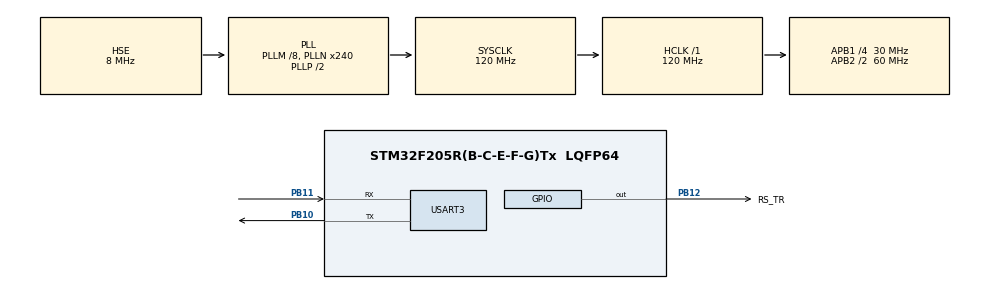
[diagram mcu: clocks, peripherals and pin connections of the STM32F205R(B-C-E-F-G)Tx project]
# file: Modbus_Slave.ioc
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Mcu.Family=STM32F2
Mcu.Name=STM32F205R(B-C-E-F-G)Tx
Mcu.Package=LQFP64
NVIC.PriorityGroup=NVIC_PRIORITYGROUP_4
NVIC.TIM5_IRQn=true\:0\:0\:false\:false\:true\:true\:true\:true
NVIC.USART3_IRQn=true\:0\:0\:false\:false\:true\:true\:true\:true
PA13.Mode=Serial_Wire
PA13.Signal=SYS_JTMS-SWDIO
PA14.Mode=Serial_Wire
PA14.Signal=SYS_JTCK-SWCLK
PB10.Mode=Asynchronous
PB10.Signal=USART3_TX
PB11.Mode=Asynchronous
PB11.Signal=USART3_RX
PB12.GPIO_Label=RS_TR
PB12.Signal=GPIO_Output
PH0-OSC_IN.Mode=HSE-External-Oscillator
PH0-OSC_IN.Signal=RCC_OSC_IN
PH1-OSC_OUT.Mode=HSE-External-Oscillator
PH1-OSC_OUT.Signal=RCC_OSC_OUT
ProjectManager.HeapSize=0x400
ProjectManager.StackSize=0x800
ProjectManager.TargetToolchain=MDK-ARM V5.32
RCC.48MHZClocksFreq_Value=60000000
RCC.AHBFreq_Value=120000000
RCC.APB1CLKDivider=RCC_HCLK_DIV4
RCC.APB1Freq_Value=30000000
RCC.APB1TimFreq_Value=60000000
RCC.APB2CLKDivider=RCC_HCLK_DIV2
RCC.APB2Freq_Value=60000000
RCC.APB2TimFreq_Value=120000000
RCC.CortexFreq_Value=120000000
RCC.HCLKFreq_Value=120000000
RCC.HSE_VALUE=8000000
RCC.HSI_VALUE=16000000
RCC.LSE_VALUE=32768
RCC.PLLM=8
RCC.PLLN=240
RCC.PLLSourceVirtual=RCC_PLLSOURCE_HSE
RCC.SYSCLKFreq_VALUE=120000000
RCC.SYSCLKSource=RCC_SYSCLKSOURCE_PLLCLK
RCC.VCOOutputFreq_Value=240000000
TIM5.Period=50
TIM5.Prescaler=60-1
USART3.VirtualMode=VM_ASYNC
VP_TIM5_VS_ClockSourceINT.Mode=Internal
board=custom

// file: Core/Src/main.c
/* USER CODE BEGIN Header */
/**
  ******************************************************************************
  * @file           : main.c
  * @brief          : Main program body
  ******************************************************************************
  * @attention
  *
  * Copyright (c) 2025 STMicroelectronics.
  * All rights reserved.
  *
  * This software is licensed under terms that can be found in the LICENSE file
  * in the root directory of this software component.
  * If no LICENSE file comes with this software, it is provided AS-IS.
  *
  ******************************************************************************
  */
/* USER CODE END Header */
#include "main.h"
#include "tim.h"
#include "usart.h"
#include "gpio.h"

/* USER CODE BEGIN Includes */
#include "modbus_slave.h"
/* USER CODE END Includes */

/* USER CODE BEGIN PV */
extern volatile USHORT usRegInputStart;
extern volatile USHORT usRegInputBuf[REG_INPUT_NREGS];
/* USER CODE END PV */

void SystemClock_Config(void);

int main(void)
{

  /* MCU Configuration--------------------------------------------------------*/

  /* Reset of all peripherals, Initializes the Flash interface and the Systick. */
  HAL_Init();

  /* Configure the system clock */
  SystemClock_Config();

  /* Initialize all configured peripherals */
  MX_GPIO_Init();
  MX_TIM5_Init();
  MX_USART3_UART_Init();
  /* USER CODE BEGIN 2 */
	modbusInit();
  /* USER CODE END 2 */

  /* Infinite loop */
  while (1)
  {

    /* USER CODE BEGIN 3 */
		eMBPoll();
    usRegInputBuf[REG_INPUT_NREGS - 2] =  HAL_GetTick() / 1000;
    usRegInputBuf[REG_INPUT_NREGS - 1] =  HAL_GetTick();
  }
  /* USER CODE END 3 */
}

void SystemClock_Config(void)
{
  RCC_OscInitTypeDef RCC_OscInitStruct = {0};
  RCC_ClkInitTypeDef RCC_ClkInitStruct = {0};

  /** Initializes the RCC Oscillators according to the specified parameters
  * in the RCC_OscInitTypeDef structure.
  */
  RCC_OscInitStruct.OscillatorType = RCC_OSCILLATORTYPE_HSE;
  RCC_OscInitStruct.HSEState = RCC_HSE_ON;
  RCC_OscInitStruct.PLL.PLLState = RCC_PLL_ON;
  RCC_OscInitStruct.PLL.PLLSource = RCC_PLLSOURCE_HSE;
  RCC_OscInitStruct.PLL.PLLM = 8;
  RCC_OscInitStruct.PLL.PLLN = 240;
  RCC_OscInitStruct.PLL.PLLP = RCC_PLLP_DIV2;
  RCC_OscInitStruct.PLL.PLLQ = 4;
  if (HAL_RCC_OscConfig(&RCC_OscInitStruct) != HAL_OK)
  {
    Error_Handler();
  }

  /** Initializes the CPU, AHB and APB buses clocks
  */
  RCC_ClkInitStruct.ClockType = RCC_CLOCKTYPE_HCLK|RCC_CLOCKTYPE_SYSCLK
                              |RCC_CLOCKTYPE_PCLK1|RCC_CLOCKTYPE_PCLK2;
  RCC_ClkInitStruct.SYSCLKSource = RCC_SYSCLKSOURCE_PLLCLK;
  RCC_ClkInitStruct.AHBCLKDivider = RCC_SYSCLK_DIV1;
  RCC_ClkInitStruct.APB1CLKDivider = RCC_HCLK_DIV4;
  RCC_ClkInitStruct.APB2CLKDivider = RCC_HCLK_DIV2;

  if (HAL_RCC_ClockConfig(&RCC_ClkInitStruct, FLASH_LATENCY_3) != HAL_OK)
  {
    Error_Handler();
  }
}

void Error_Handler(void)
{
  __disable_irq();
  while (1)
  {
  }
}
